# UNIPRO_REG register map
Vendor: Texas Instruments
Peripheral module from a debugger description file (folder omap5430_ES2_PUBLIC).
Registers are 32-bit, access per field, reset 0x0 unless marked. A register's access mark holds for its fields unless they carry their own. Offsets are as the file gives them; lines under a group give offsets from that group; [hi:lo] are bit positions; {n}, {i} and the like mark numbered series; 'fields as' and 'values as' point back to an identical list; <NAME> marks a mode.

## UNIPRO_REG (part 1 of 2)
0x00 UNIPRO_REVISION ro reset not defined — IP revision code register.
  [31:0] REVISION — Controller revision number. (TI internal data)
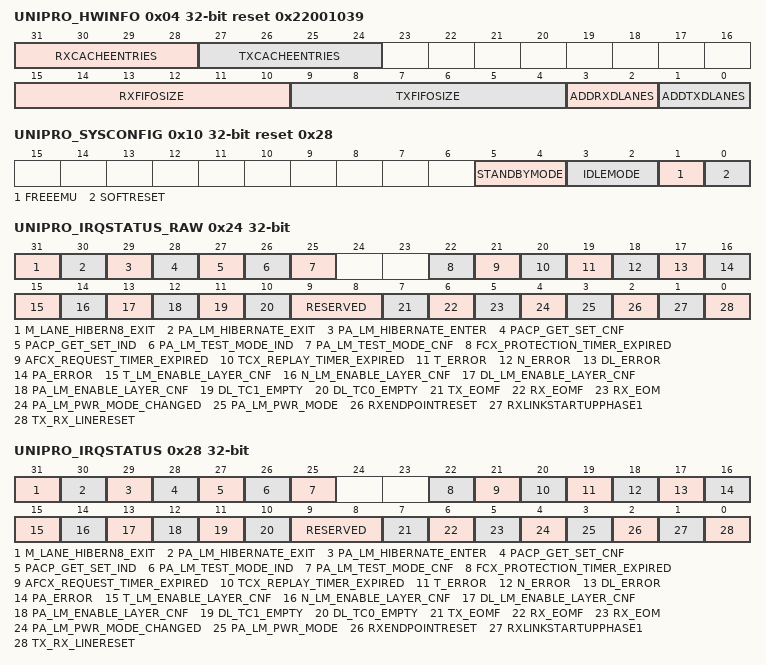
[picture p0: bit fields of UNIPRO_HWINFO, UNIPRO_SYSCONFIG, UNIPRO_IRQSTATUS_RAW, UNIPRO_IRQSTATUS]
0x04 UNIPRO_HWINFO ro reset 0x22001039 — Hardware module configuration register
  [31:28] RXCACHEENTRIES — Defines the number of RX descriptor cache entries as : 0 -- 1 entry 1 -- 2 entries 2 -- 4 entries 3 -- 6 entries ... 15 -- 30 entries or more
  [27:24] TXCACHEENTRIES — Defines the number of TX descriptor cache entries as : 0 -- 1 entry 1 -- 2 entries 2 -- 4 entries 3 -- 6 entries ... 15 -- 30 entries or more
  [15:10] RXFIFOSIZE — Indicates RX FiFo size, in terms of number of blocks of 128 * 64b entries. Rx FiFo size (bytes) = 128 * 8 * RxFiFoSize 0 indicates less than 128*64b
  [9:4] TXFIFOSIZE — Indicates TX FiFo size, in terms of number of blocks of 128 * 64b entries. TX FiFo size (bytes) = 128 * 8 * TxFiFoSize 0 indicates less than 128 * 64b.
  [3:2] ADDRXDLANES — Number of additional Rx data lanes on top of lane 1 0: no additional -- one Rx data lane total ... 3 : 3 additional -- 4 Rx data lanes total
  [1:0] ADDTXDLANES — Number of additional TX data lanes on top of lane 1 0: no additional -- one TX data lane total ... 3 : 3 additional -- 4 TX data lanes total
0x10 UNIPRO_SYSCONFIG reset 0x28 — Clock management configuration
  [5:4] STANDBYMODE rw — Configuration of the local initiator state management mode. By definition, initiator may generate read/write transaction as long as it is out of STANDBY state. 0x0: Force-standby mode: local initiator is unconditionally placed in standby state. Backup mode, for debug only. 0x1: No-standby mode: local initiator is unconditionally placed out of standby state. Backup mode, for debug only. 0x2: Smart-standby mode: local initiator standby status depends on local conditions, i.e. the module's functional requirement from the initiator. IP module shall not generate (initiator-related) wakeup events. 0x3: Smart-Standby wakeup-capable mode: local initiator standby status depends on local conditions, i.e. the module's functional requirement from the initiator. IP module may generate (master-related) wakeup events when in standby state. Mode is only relevant if the appropriate IP module 'mwakeup' output is implemented.
  [3:2] IDLEMODE rw — Configuration of the local target state management mode. By definition, target can handle read/write transaction as long as it is out of IDLE state. 0x0: Force-idle mode: local target's idle state follows (acknowledges) the system's idle requests unconditionally, i.e. regardless of the IP module's internal requirements. Backup mode, for debug only. 0x1: No-idle mode: local target never enters idle state. Backup mode, for debug only. 0x2: Smart-idle mode: local target's idle state eventually follows (acknowledges) the system's idle requests, depending on the IP module's internal requirements. IP module shall not generate (IRQ- or DMA-request-related) wakeup events. 0x3: Smart-idle wakeup-capable mode: local target's idle state eventually follows (acknowledges) the system's idle requests, depending on the IP module's internal requirements. IP module may generate (IRQ- or DMA-request-related) wakeup events when in idle state. Mode is only relevant if the appropriate IP module 'swakeup' output(s) is (are) implemented.
  [1] FREEEMU rw — Sensitivity to emulation (debug) suspend input signal. 0: IP module is sensitive to emulation suspend 1: IP module is not sensitive to emulation suspend
  [0] SOFTRESET rw — Software reset. (Optional) Read 0: Reset done, no pending action Write 0: No action Write 1: Initiate software reset Read 1: Reset (software or other) ongoing
0x24 UNIPRO_IRQSTATUS_RAW access not given — Per-event raw interrupt status vector, line #0. Raw status is set even if event is not enabled. Write 1 to set the (raw) status, mostly for debug.
  [31] M_LANE_HIBERN8_EXIT — M_LANE_HIBERN8Exit occured on logical lane 0. Used as async wakeup source. (access RW W1toSet)
  [30] PA_LM_HIBERNATE_EXIT — Hibernate exit request has completed and result is in PowerChangeResultCode. (access RW W1toSet)
  [29] PA_LM_HIBERNATE_ENTER — Hibernate enter request has completed and result is in PowerChangeResultCode. (access RW W1toSet)
  [28] PACP_GET_SET_CNF — Indicates reception of a DME_PEER_GET.cnf or DME_PEER_SET.cnf (access RW W1toClr)
  [27] PACP_GET_SET_IND — Indicates reception of a DME_PEER_GET.ind or DME_PEER_SET.ind (access RW W1toClr)
  [26] PA_LM_TEST_MODE_IND — Indicates the reception of a request to put the PA Layer in a specified test mode. Generated when a PACP_TEST_MODE_req frame is received before the start of the Link Startup sequence. (access RW W1toClr)
  [25] PA_LM_TEST_MODE_CNF — Reports the completion of a test mode request. Generated in response to a PA_LM_TEST_MODE.req from the DME, after having sent the PACP_TEST_MODE_req frame. (access RW W1toClr)
  [22] FCX_PROTECTION_TIMER_EXPIRED — Indicates that the FC0_PROTECTION_TIMER or FC1_PROTECTION_TIMER has expired. (access RW W1toSet)
  [21] AFCX_REQUEST_TIMER_EXPIRED — Indicates that the AFC0_REQUEST_TIMER or AFC1_REQUEST_TIMER has expired. (access RW W1toSet)
  [20] TCX_REPLAY_TIMER_EXPIRED — Indicates that the TC0_REPLAY_TIMER or TC1_REPLAY_TIMER has expired. (access RW W1toSet)
  [19] T_ERROR — Indicates that a T_PDU has been discarded (combines UNSUPPORTED_HEADER_TYPE, UNKNOWN_CPORTID, NO_CONNECTION_RX, CONTROLLED_SEGMENT_DROPPING, BAD_TC, SAFETY_VALVE_DROPPING). (access RW W1toSet)
  [18] N_ERROR — Indicates that an N_PDU has been discarded (combines BAD_DEVICEID_ENC and LHDR_TRAP_PACKET_DROPPING). (access RW W1toSet)
  [17] DL_ERROR — Indicates an error has occurred on Rx link which causes an NAC to be reported or that a NAC has been received (combines NAC_RECEIVED, CRC_ERROR, RX_BUFFER_OVERFLOW, MAX_FRAME_LENGTH_EXCEEDED, WRONG_SEQUENCE_NUMBER, AFC_FRAME_SYNTAX_ERROR, NAC_FRAME_SYNTAX_ERROR, EOF_SYNTAX_ERROR, FRAME_SYNTAX_ERROR, BAD_CTRL_SYMBOL_TYPE, PA_ERROR_IND_RECEIVED). (access RW W1toSet)
  [16] PA_ERROR — Indicates that a PA_ERROR has occurred (combines BAD_PHY_SYMBOL, UNMAPPED_PHY_ESC_SYMBOL, UNEXPECTED_PHY_ESC_SYMBOL, BAD_PA_PARAM). (access RW W1toSet)
  [15] T_LM_ENABLE_LAYER_CNF — Set when Transport (L4) layer initialization phase is complete. (access RW W1toSet)
  [14] N_LM_ENABLE_LAYER_CNF — Set when Network (L3) layer initialization phase is complete. (access RW W1toSet)
  [13] DL_LM_ENABLE_LAYER_CNF — Set when Data link (L2) layer initialization phase is complete. (access RW W1toSet)
  [12] PA_LM_ENABLE_LAYER_CNF — Set when Linkstartup (L1.5 initialization) phase is complete. (access RW W1toSet)
  [11] DL_TC1_EMPTY — All transmitted frames on TC1 have been acknowledged (access RW W1toSet)
  [10] DL_TC0_EMPTY — All transmitted frames on TC0 have been acknowledged (access RW W1toSet)
  [9:8] RESERVED ro
  [7] TX_EOMF — End of Message Fragment transmitted (access RW W1toSet)
  [6] RX_EOMF — End of Message Fragment crossed (access RW W1toSet)
  [5] RX_EOM — End of Message received (access RW W1toSet)
  [4] PA_LM_PWR_MODE_CHANGED — A Power Change Request has been accepted and the result is available in PowerChangeResultCode. (access RW W1toSet)
  [3] PA_LM_PWR_MODE — A Power Change Request has been received and PAPowerModeUserData is available. (access RW W1toSet)
  [2] RXENDPOINTRESET — EndPointReset trigger ('TRG_EPR') has been received over the link. (access RW W1toSet)
  [1] RXLINKSTARTUPPHASE1 — 'TRG_UPR0' trigger event has been received over the PHY and the module has not yet entered the Link Startup sequence. (access RW W1toSet)
  [0] TX_RX_LINERESET — LINERESET received on M-RX or M-TX. (access RW W1toSet)
0x28 UNIPRO_IRQSTATUS access not given — Per-event 'enabled' interrupt status vector, line #0. Enabled status isn't set unless event is enabled. Write 1 to clear the status after interrupt has been serviced (raw status gets cleared, i.e. even if not enabled).
  [31] M_LANE_HIBERN8_EXIT — M_LANE_HIBERN8Exit occured on logical lane 0. Used as async wakeup source. (access RW W1toClr)
  [30] PA_LM_HIBERNATE_EXIT — Hibernate exit request has completed and result is in PowerChangeResultCode. (access RW W1toClr)
  [29] PA_LM_HIBERNATE_ENTER — Hibernate enter request has completed and result is in PowerChangeResultCode. (access RW W1toClr)
  [28] PACP_GET_SET_CNF — Indicates reception of a DME_PEER_GET.cnf or DME_PEER_SET.cnf (access RW W1toClr)
  [27] PACP_GET_SET_IND — Indicates reception of a DME_PEER_GET.ind or DME_PEER_SET.ind (access RW W1toClr)
  [26] PA_LM_TEST_MODE_IND — Indicates the reception of a request to put the PA Layer in a specified test mode. Generated when a PACP_TEST_MODE_req frame is received before the start of the Link Startup sequence. (access RW W1toClr)
  [25] PA_LM_TEST_MODE_CNF — Reports the completion of a test mode request. Generated in response to a PA_LM_TEST_MODE.req from the DME, after having sent the PACP_TEST_MODE_req frame. (access RW W1toClr)
  [22] FCX_PROTECTION_TIMER_EXPIRED — Indicates that the FC0_PROTECTION_TIMER or FC1_PROTECTION_TIMER has expired. (access RW W1toClr)
  [21] AFCX_REQUEST_TIMER_EXPIRED — Indicates that the AFC0_REQUEST_TIMER or AFC1_REQUEST_TIMER has expired. (access RW W1toClr)
  [20] TCX_REPLAY_TIMER_EXPIRED — Indicates that the TC0_REPLAY_TIMER or TC1_REPLAY_TIMER has expired. (access RW W1toClr)
  [19] T_ERROR — Indicates that a T_PDU has been discarded (combines UNSUPPORTED_HEADER_TYPE, UNKNOWN_CPORTID, NO_CONNECTION_RX, CONTROLLED_SEGMENT_DROPPING, BAD_TC, SAFETY_VALVE_DROPPING). (access RW W1toClr)
  [18] N_ERROR — Indicates that an N_PDU has been discarded (combines BAD_DEVICEID_ENC and LHDR_TRAP_PACKET_DROPPING). (access RW W1toClr)
  [17] DL_ERROR — Indicates an error has occurred on Rx link which causes an NAC to be reported or that a NAC has been received (combines NAC_RECEIVED, CRC_ERROR, RX_BUFFER_OVERFLOW, MAX_FRAME_LENGTH_EXCEEDED, WRONG_SEQUENCE_NUMBER, AFC_FRAME_SYNTAX_ERROR, NAC_FRAME_SYNTAX_ERROR, EOF_SYNTAX_ERROR, FRAME_SYNTAX_ERROR, BAD_CTRL_SYMBOL_TYPE, PA_ERROR_IND_RECEIVED). (access RW W1toClr)
  [16] PA_ERROR — Indicates that a PA_ERROR has occurred (combines BAD_PHY_SYMBOL, UNMAPPED_PHY_ESC_SYMBOL, UNEXPECTED_PHY_ESC_SYMBOL, BAD_PA_PARAM). (access RW W1toClr)
  [15] T_LM_ENABLE_LAYER_CNF — Set when Transport (L4) layer initialization phase is complete. (access RW W1toClr)
  [14] N_LM_ENABLE_LAYER_CNF — Set when Network (L3) layer initialization phase is complete. (access RW W1toClr)
  [13] DL_LM_ENABLE_LAYER_CNF — Set when Data link (L2) layer initialization phase is complete. (access RW W1toClr)
  [12] PA_LM_ENABLE_LAYER_CNF — Set when Linkstartup (L1.5 initialization) phase is complete. (access RW W1toClr)
  [11] DL_TC1_EMPTY — All transmitted frames on TC1 have been acknowledged (access RW W1toClr)
  [10] DL_TC0_EMPTY — All transmitted frames on TC0 have been acknowledged (access RW W1toClr)
  [9:8] RESERVED ro
  [7] TX_EOMF — End of Message Fragment transmitted (access RW W1toClr)
  [6] RX_EOMF — End of Message Fragment crossed (access RW W1toClr)
  [5] RX_EOM — End of Message received (access RW W1toClr)
  [4] PA_LM_PWR_MODE_CHANGED — A Power Change Request has been accepted and the result is available in PowerChangeResultCode. (access RW W1toClr)
  [3] PA_LM_PWR_MODE — A Power Change Request has been received and PAPowerModeUserData is available. (access RW W1toClr)
  [2] RXENDPOINTRESET — EndPointReset trigger ('TRG_EPR') has been received over the link. (access RW W1toClr)
  [1] RXLINKSTARTUPPHASE1 — 'TRG_UPR0' trigger event has been received over the PHY and the module has not yet entered the Link Startup sequence. (access RW W1toClr)
  [0] TX_RX_LINERESET — LINERESET received on M-RX or M-TX (access RW W1toClr)
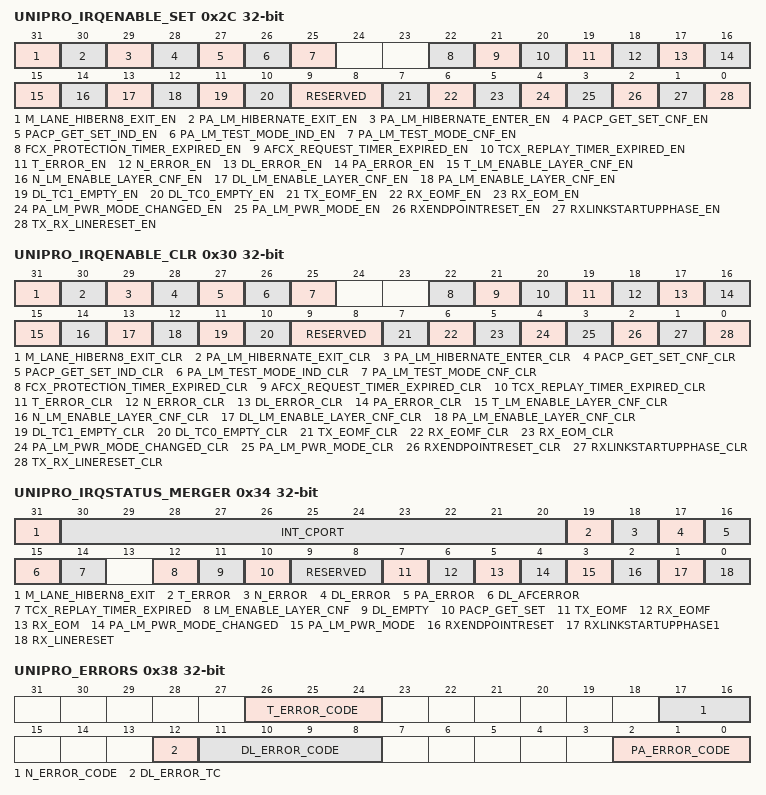
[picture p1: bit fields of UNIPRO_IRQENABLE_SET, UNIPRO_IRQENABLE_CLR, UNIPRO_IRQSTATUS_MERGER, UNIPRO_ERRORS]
0x2C UNIPRO_IRQENABLE_SET access not given — Per-event 'enabled' interrupt status vector, line #0. Enabled status isn't set unless event is enabled. Write 1 to clear the status after interrupt has been serviced (raw status gets cleared, i.e. even if not enabled).
  [31] M_LANE_HIBERN8_EXIT_EN — M_LANE_HIBERN8Exit occured on logical lane 0. Used as async wakeup source. (access RW W1toSet)
  [30] PA_LM_HIBERNATE_EXIT_EN — Hibernate exit request has completed and result is in PowerChangeResultCode. (access RW W1toSet)
  [29] PA_LM_HIBERNATE_ENTER_EN — Hibernate enter request has completed and result is in PowerChangeResultCode. (access RW W1toSet)
  [28] PACP_GET_SET_CNF_EN — Indicates reception of a DME_PEER_GET.cnf or DME_PEER_SET.cnf (access RW W1toClr)
  [27] PACP_GET_SET_IND_EN — Indicates reception of a DME_PEER_GET.ind or DME_PEER_SET.ind (access RW W1toClr)
  [26] PA_LM_TEST_MODE_IND_EN — Indicates the reception of a request to put the PA Layer in a specified test mode. Generated when a PACP_TEST_MODE_req frame is received before the start of the Link Startup sequence. (access RW W1toClr)
  [25] PA_LM_TEST_MODE_CNF_EN — Reports the completion of a test mode request. Generated in response to a PA_LM_TEST_MODE.req from the DME, after having sent the PACP_TEST_MODE_req frame. (access RW W1toClr)
  [22] FCX_PROTECTION_TIMER_EXPIRED_EN — Indicates that the FC0_PROTECTION_TIMER or FC1_PROTECTION_TIMER has expired. (access RW W1toSet)
  [21] AFCX_REQUEST_TIMER_EXPIRED_EN — Indicates that the AFC0_REQUEST_TIMER or AFC1_REQUEST_TIMER has expired. (access RW W1toSet)
  [20] TCX_REPLAY_TIMER_EXPIRED_EN — Indicates that the TC0_REPLAY_TIMER or TC1_REPLAY_TIMER has expired. (access RW W1toSet)
  [19] T_ERROR_EN — Indicates that a T_PDU has been discarded (combines UNSUPPORTED_HEADER_TYPE, UNKNOWN_CPORTID, NO_CONNECTION_RX, CONTROLLED_SEGMENT_DROPPING, BAD_TC, SAFETY_VALVE_DROPPING). (access RW W1toSet)
  [18] N_ERROR_EN — Indicates that an N_PDU has been discarded (combines BAD_DEVICEID_ENC and LHDR_TRAP_PACKET_DROPPING). (access RW W1toSet)
  [17] DL_ERROR_EN — Indicates an error has occurred on Rx link which causes an NAC to be reported or that a NAC has been received (combines NAC_RECEIVED, CRC_ERROR, RX_BUFFER_OVERFLOW, MAX_FRAME_LENGTH_EXCEEDED, WRONG_SEQUENCE_NUMBER, AFC_FRAME_SYNTAX_ERROR, NAC_FRAME_SYNTAX_ERROR, EOF_SYNTAX_ERROR, FRAME_SYNTAX_ERROR, BAD_CTRL_SYMBOL_TYPE, PA_ERROR_IND_RECEIVED). (access RW W1toSet)
  [16] PA_ERROR_EN — Indicates that a PA_ERROR has occurred (combines BAD_PHY_SYMBOL, UNMAPPED_PHY_ESC_SYMBOL, UNEXPECTED_PHY_ESC_SYMBOL, BAD_PA_PARAM). (access RW W1toSet)
  [15] T_LM_ENABLE_LAYER_CNF_EN — Set when Transport (L4) layer initialization phase is complete. (access RW W1toSet)
  [14] N_LM_ENABLE_LAYER_CNF_EN — Set when Network (L3) layer initialization phase is complete. (access RW W1toSet)
  [13] DL_LM_ENABLE_LAYER_CNF_EN — Set when Data link (L2) layer initialization phase is complete. (access RW W1toSet)
  [12] PA_LM_ENABLE_LAYER_CNF_EN — Set when Linkstartup (L1.5 initialization) phase is complete. (access RW W1toSet)
  [11] DL_TC1_EMPTY_EN — All transmitted frames on TC1 have been acknowledged (access RW W1toSet)
  [10] DL_TC0_EMPTY_EN — All transmitted frames on TC0 have been acknowledged (access RW W1toSet)
  [9:8] RESERVED ro
  [7] TX_EOMF_EN — End of Message Fragment transmitted (access RW W1toSet)
  [6] RX_EOMF_EN — End of Message Fragment crossed (access RW W1toSet)
  [5] RX_EOM_EN — End of Message received (access RW W1toSet)
  [4] PA_LM_PWR_MODE_CHANGED_EN — A Power Change Request has been accepted and the result is available in PowerChangeResultCode. (access RW W1toSet)
  [3] PA_LM_PWR_MODE_EN — A Power Change Request has been received and PAPowerModeUserData is available. (access RW W1toSet)
  [2] RXENDPOINTRESET_EN — EndPointReset trigger ('TRG_EPR') has been received over the link. (access RW W1toSet)
  [1] RXLINKSTARTUPPHASE_EN — 'TRG_UPR0' trigger event has been received over the PHY and the module has not yet entered the Link Startup sequence. (access RW W1toSet)
  [0] TX_RX_LINERESET_EN — LINERESET received on M-RX or M-TX (access RW W1toSet)
0x30 UNIPRO_IRQENABLE_CLR access not given — Per-event 'clear' interrupt status vector, line #0. Readout equal to corresponding _SET register Write 1 to clear the status after interrupt has been serviced (raw status gets cleared, i.e. even if not enabled).
  [31] M_LANE_HIBERN8_EXIT_CLR — M_LANE_HIBERN8Exit occured on logical lane 0. Used as async wakeup source. (access RW W1toClr)
  [30] PA_LM_HIBERNATE_EXIT_CLR — Hibernate exit request has completed and result is in PowerChangeResultCode. (access RW W1toClr)
  [29] PA_LM_HIBERNATE_ENTER_CLR — Hibernate enter request has completed and result is in PowerChangeResultCode. (access RW W1toClr)
  [28] PACP_GET_SET_CNF_CLR — Indicates reception of a DME_PEER_GET.cnf or DME_PEER_SET.cnf (access RW W1toClr)
  [27] PACP_GET_SET_IND_CLR — Indicates reception of a DME_PEER_GET.ind or DME_PEER_SET.ind (access RW W1toClr)
  [26] PA_LM_TEST_MODE_IND_CLR — Indicates the reception of a request to put the PA Layer in a specified test mode. Generated when a PACP_TEST_MODE_req frame is received before the start of the Link Startup sequence. (access RW W1toClr)
  [25] PA_LM_TEST_MODE_CNF_CLR — Reports the completion of a test mode request. Generated in response to a PA_LM_TEST_MODE.req from the DME, after having sent the PACP_TEST_MODE_req frame. (access RW W1toClr)
  [22] FCX_PROTECTION_TIMER_EXPIRED_CLR — Indicates that the FC0_PROTECTION_TIMER or FC1_PROTECTION_TIMER has expired. (access RW W1toClr)
  [21] AFCX_REQUEST_TIMER_EXPIRED_CLR — Indicates that the AFC0_REQUEST_TIMER or AFC1_REQUEST_TIMER has expired. (access RW W1toClr)
  [20] TCX_REPLAY_TIMER_EXPIRED_CLR — Indicates that the TC0_REPLAY_TIMER or TC1_REPLAY_TIMER has expired. (access RW W1toClr)
  [19] T_ERROR_CLR — Indicates that a T_PDU has been discarded (combines UNSUPPORTED_HEADER_TYPE, UNKNOWN_CPORTID, NO_CONNECTION_RX, CONTROLLED_SEGMENT_DROPPING, BAD_TC, SAFETY_VALVE_DROPPING). (access RW W1toClr)
  [18] N_ERROR_CLR — Indicates that an N_PDU has been discarded (combines BAD_DEVICEID_ENC and LHDR_TRAP_PACKET_DROPPING). (access RW W1toClr)
  [17] DL_ERROR_CLR — Indicates an error has occurred on Rx link which causes an NAC to be reported or that a NAC has been received (combines NAC_RECEIVED, CRC_ERROR, RX_BUFFER_OVERFLOW, MAX_FRAME_LENGTH_EXCEEDED, WRONG_SEQUENCE_NUMBER, AFC_FRAME_SYNTAX_ERROR, NAC_FRAME_SYNTAX_ERROR, EOF_SYNTAX_ERROR, FRAME_SYNTAX_ERROR, BAD_CTRL_SYMBOL_TYPE, PA_ERROR_IND_RECEIVED). (access RW W1toClr)
  [16] PA_ERROR_CLR — Indicates that a PA_ERROR has occurred (combines BAD_PHY_SYMBOL, UNMAPPED_PHY_ESC_SYMBOL, UNEXPECTED_PHY_ESC_SYMBOL, BAD_PA_PARAM). (access RW W1toClr)
  [15] T_LM_ENABLE_LAYER_CNF_CLR — Set when Transport (L4) layer initialization phase is complete. (access RW W1toClr)
  [14] N_LM_ENABLE_LAYER_CNF_CLR — Set when Network (L3) layer initialization phase is complete. (access RW W1toClr)
  [13] DL_LM_ENABLE_LAYER_CNF_CLR — Set when Data link (L2) layer initialization phase is complete. (access RW W1toClr)
  [12] PA_LM_ENABLE_LAYER_CNF_CLR — Set when Linkstartup (L1.5 initialization) phase is complete. (access RW W1toClr)
  [11] DL_TC1_EMPTY_CLR — All transmitted frames on TC1 have been acknowledged (access RW W1toClr)
  [10] DL_TC0_EMPTY_CLR — All transmitted frames on TC0 have been acknowledged (access RW W1toClr)
  [9:8] RESERVED ro
  [7] TX_EOMF_CLR — End of Message Fragment transmitted (access RW W1toClr)
  [6] RX_EOMF_CLR — End of Message Fragment crossed (access RW W1toClr)
  [5] RX_EOM_CLR — End of Message received (access RW W1toClr)
  [4] PA_LM_PWR_MODE_CHANGED_CLR — A Power Change Request has been accepted and the result is available in PowerChangeResultCode. (access RW W1toClr)
  [3] PA_LM_PWR_MODE_CLR — A Power Change Request has been received and PAPowerModeUserData is available. (access RW W1toClr)
  [2] RXENDPOINTRESET_CLR — EndPointReset trigger ('TRG_EPR') has been received over the link. (access RW W1toClr)
  [1] RXLINKSTARTUPPHASE_CLR — 'TRG_UPR0' trigger event has been received over the PHY and the module has not yet entered the Link Startup sequence. (access RW W1toClr)
  [0] TX_RX_LINERESET_CLR — LINERESET received on M-RX or M-TX (access RW W1toClr)
0x34 UNIPRO_IRQSTATUS_MERGER ro — This register is a simple IRQ merger. It does not correspond to real register
  [31] M_LANE_HIBERN8_EXIT — M_LANE_HIBERN8Exit occured on logical lane 0. Used as async wakeup source.
  [30:20] INT_CPORT — cport identifier related to the first T_ERROR that has occurred. Cleared when T_ERROR_CODE is cleared.
  [19] T_ERROR — Indicates that a T_PDU has been discarded (combines UNSUPPORTED_HEADER_TYPE, UNKNOWN_CPORTID, NO_CONNECTION_RX, CONTROLLED_SEGMENT_DROPPING, BAD_TC, SAFETY_VALVE_DROPPING).
  [18] N_ERROR — Indicates that an N_PDU has been discarded (combines BAD_DEVICEID_ENC and LHDR_TRAP_PACKET_DROPPING).
  [17] DL_ERROR — Indicates an error has occurred on Rx link which causes an NAC to be reported or that a NAC has been received (combines NAC_RECEIVED, CRC_ERROR, RX_BUFFER_OVERFLOW, MAX_FRAME_LENGTH_EXCEEDED, WRONG_SEQUENCE_NUMBER, AFC_FRAME_SYNTAX_ERROR, NAC_FRAME_SYNTAX_ERROR, EOF_SYNTAX_ERROR, FRAME_SYNTAX_ERROR, BAD_CTRL_SYMBOL_TYPE, PA_ERROR_IND_RECEIVED).
  [16] PA_ERROR — Indicates that a PA_ERROR has occurred (combines BAD_PHY_SYMBOL, UNMAPPED_PHY_ESC_SYMBOL, UNEXPECTED_PHY_ESC_SYMBOL, BAD_PA_PARAM).
  [15] DL_AFCERROR — Merges: &gt; AFCX_REQUEST_TIMER_EXPIRED &gt; FCX_PROTECTION_TIMER_EXPIRED
  [14] TCX_REPLAY_TIMER_EXPIRED — Indicates that the TC0_REPLAY_TIMER or TC1_REPLAY_TIMER has expired.
  [12] LM_ENABLE_LAYER_CNF — Indicates that the current LAYER ENABLE command has completed. Merges &gt; PA_LM_ENABLE_LAYER_CNF &gt; DL_LM_ENABLE_LAYER_CNF &gt; N_LM_ENABLE_LAYER_CNF &gt; T_LM_ENABLE_LAYER_CNF
  [11] DL_EMPTY — Merges &gt; DL_TC0_empty &gt; DL_TC1_empty
  [10] PACP_GET_SET — Merges &gt;PACP_GET_SET_IND &gt;PACP_GET_SET_CNF &gt;PA_LM_TEST_MODE_CNF &gt;PA_LM_TEST_MODE_IND
  [9:8] RESERVED
  [7] TX_EOMF — End of Message Fragment transmitted
  [6] RX_EOMF — End of Message Fragment crossed
  [5] RX_EOM — End of Message received
  [4] PA_LM_PWR_MODE_CHANGED — Merges &gt; PA_LM_PWR_MODE_CHANGED &gt; PA_LM_HIBERNATE_ENTER &gt; PA_LM_HIBERNATE_EXIT
  [3] PA_LM_PWR_MODE — A Power Change Request has been received and PAPowerModeUserData is available.
  [2] RXENDPOINTRESET — Indicates that a Rx EndPoint reset has occured
  [1] RXLINKSTARTUPPHASE1 — Indicates that the Rx link startup started
  [0] RX_LINERESET — LINERESET received on M-RX
0x38 UNIPRO_ERRORS access not given — This register contains the error codes related to all UniPro ERROR interrupts.
  [26:24] T_ERROR_CODE — The code of the received T_ERROR: 0: No T_ERROR occurred 1: UNSUPPORTED_HEADER_TYPE - T_PDU whose header contains unsupported values 2: UNKNOWN_CPORTID - The C-Port a received T_PDU is targeting does not exist 3: NO_CONNECTION_RX - T_PDU targeting a C-Port that has no established Connection 4: CONTROLLED_SEGMENT_DROPPING - Segment was dropped at the receiver due to insufficient buffer space 5: BAD_TC - T_PDU with a Traffic Class that is different than the T_TrafficClass attribute of the destination C-Port 6: reserved 7: SAFETY_VALVE_DROPPING - C-Port Safety Valve mechanism has discarded data. Write to clear. (access RW WtoClr)
  [17:16] N_ERROR_CODE — The code of the received N_ERROR: 0: No N_ERROR occurred 1: Reserved 2: BAD_DEVICEID_ENC - an N_PDU was received with a DestDeviceID_Enc less than N_DeviceID 3: LHDR_TRAP_PACKET_DROPPING - Indicates that a Long Header Packet has been dropped because the L3 extension was not available to accept the Packet Write to clear. (access RW WtoClr)
  [12] DL_ERROR_TC — Indicates the TC for which a DL_ERROR occurred (valid only for TCx_REPLAY_TIMER_EXPIRED, AFCx_REQUEST_TIMER_EXPIRED, FCx_PROTECTION_TIMER_EXPIRED) 0: Traffic class 0 1: Traffic class 1 Write to clear. (access RW WtoClr)
  [11:8] DL_ERROR_CODE — The code of the received DL_ERROR: 0: No DL_ERROR occurred 1: NAC_RECEIVED - NAC Frame has been received 2: TCx_REPLAY_TIMER_EXPIRED - TCx_REPLAY_TIMER has expired 3: AFCx_REQUEST_TIMER_EXPIRED - AFCx_REQUEST_TIMER has expired 4: FCx_PROTECTION_TIMER_EXPIRED - FCx_PROTECTION_TIMER has expired 5: CRC_ERROR - CRC error has been detected on either a Data or a Control Frame 6: RX_BUFFER_OVERFLOW - RX buffer overflows 7: MAX_FRAME_LENGTH_EXCEEDED - a Frame with a payload longer than the DL_MTU 8: WRONG_SEQUENCE_NUMBER - a correct Frame with a wrong Frame Sequence Number 9: AFC_FRAME_SYNTAX_ERROR - AFC symbol not followed by two data symbols 10: NAC_FRAME_SYNTAX_ERROR - NAC symbol not followed by one data symbol 11: EOF_SYNTAX_ERROR - EOF_EVEN symbol not followed by one data symbol 12: FRAME_SYNTAX_ERROR - unexpected framing sequence 13: BAD_CTRL_SYMBOL_TYPE - unsupported Data or Control Frame 14: PA_ERROR_IND_RECEIVED - PA_ERROR.ind has been received other: reserved Write to clear. (access RW WtoClr)
  [2:0] PA_ERROR_CODE — The code of the received PA_ERROR: 0: No PA_ERROR occurred 1: BAD_PHY_SYMBOL - an invalid 9b symbol is received 2: UNMAPPED_PHY_ESC_SYMBOL - an undefined 9b symbol is received 3: UNEXPECTED_PHY_ESC_SYMBOL - C400 or C417 is received for PA_PDU[7:0] 4: BAD_PA_PARAM - ESC_PA with EscParam_PA other than 0 is received other: reserved Write to clear. (access RW WtoClr)
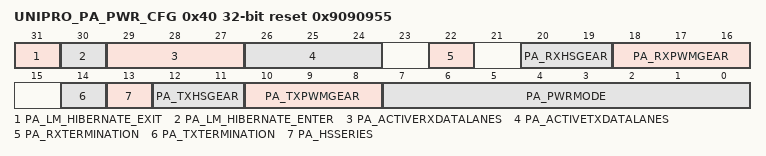
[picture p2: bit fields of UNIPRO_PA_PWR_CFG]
0x40 UNIPRO_PA_PWR_CFG access not given reset 0x9090955 — UNIPRO PA Power and Lane Configuration register. This register contains information about the programmed number of Active Lanes and Power Modes on Tx and Rx.
  [31] PA_LM_HIBERNATE_EXIT rw — Writing 1 to this bit will trigger the Hibernate Exit sequence.
  [30] PA_LM_HIBERNATE_ENTER rw — Writing 1 to this bit will trigger the Hibernate Enter sequence.
  [29:27] PA_ACTIVERXDATALANES — Defines the number of Active Rx Data Lanes. Read value returns current Active Lanes updated after Linkstartup or succesfull power mode change. Writes directed to shadow register used for power mode change procedure. (access RW RSpecial)
  [26:24] PA_ACTIVETXDATALANES — Defines the number of Active Tx Data Lanes. Read value returns current Active Lanes updated after Linkstartup or succesfull power mode change. Writes directed to shadow register used for power mode change procedure. (access RW RSpecial)
  [22] PA_RXTERMINATION — Rx Termination Read value returns current Power Mode updated after Linkstartup or succesfull power mode change. Writes directed to shadow register used for power mode change procedure. (access RW RSpecial)
  [20:19] PA_RXHSGEAR — RX Gear in High Speed Mode 0: reserved 1: HS_G1 2: HS_G2 3: HS_G3 Read value returns current Power Mode updated after Linkstartup or succesfull power mode change. Writes directed to shadow register used for power mode change procedure. (access RW RSpecial)
  [18:16] PA_RXPWMGEAR — RX Gear in PWM Mode 0: reserved 1: PWM_G1 2: PWM_G2 3: PWM_G3 4: PWM_G4 5: PWM_G5 6: PWM_G6 7: PWM_G7 Read value returns current Power Mode updated after Linkstartup or succesfull power mode change. Writes directed to shadow register used for power mode change procedure. (access RW RSpecial)
  [14] PA_TXTERMINATION — Tx Termination Read value returns current Power Mode updated after Linkstartup or succesfull power mode change. Writes directed to shadow register used for power mode change procedure. (access RW RSpecial)
  [13] PA_HSSERIES — TX and Rx Frequency Series in High Speed Mode 0: A 1: B Read value returns current Power Mode updated after Linkstartup or succesfull power mode change. Writes directed to shadow register used for power mode change procedure. (access RW RSpecial)
  [12:11] PA_TXHSGEAR — TX Gear in High Speed Mode 0: reserved 1: HS_G1 2: HS_G2 3: HS_G3 Read value returns current Power Mode updated after Linkstartup or succesfull power mode change. Writes directed to shadow register used for power mode change procedure. (access RW RSpecial)
  [10:8] PA_TXPWMGEAR — TX Gear in PWM Mode 0: reserved 1: PWM_G1 2: PWM_G2 3: PWM_G3 4: PWM_G4 5: PWM_G5 6: PWM_G6 7: PWM_G7 Read value returns current Power Mode updated after Linkstartup or succesfull power mode change. Writes directed to shadow register used for power mode change procedure. (access RW RSpecial)
  [7:0] PA_PWRMODE — Defines the TX/RX Power mode. TX[b3:b0] RX[b7:b4] 0 : Off 1: Fast_Mode 2: Slow_Mode 3: Hibernate 4: FastAuto_Mode 5: SlowAuto_Mode 15: UNCHANGED Read value returns current Power Mode updated after Linkstartup or succesfull power mode change. Writes directed to shadow register used for power mode change procedure. (access RW RSpecial)
